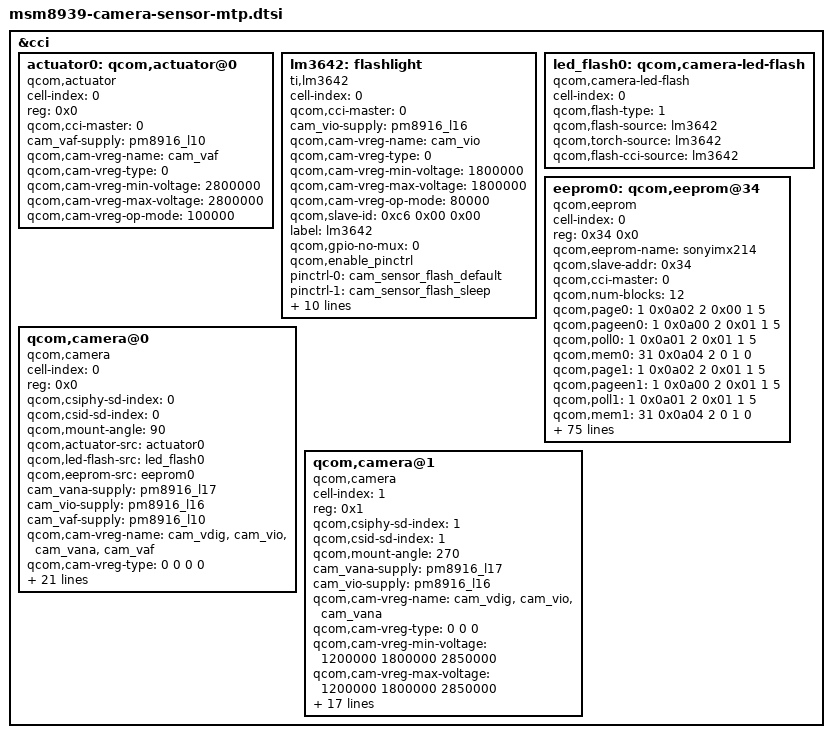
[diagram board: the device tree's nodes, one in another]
/*
 * Copyright (c) 2014, The Linux Foundation. All rights reserved.
 *
 * This program is free software; you can redistribute it and/or modify
 * it under the terms of the GNU General Public License version 2 and
 * only version 2 as published by the Free Software Foundation.
 *
 * This program is distributed in the hope that it will be useful,
 * but WITHOUT ANY WARRANTY; without even the implied warranty of
 * MERCHANTABILITY or FITNESS FOR A PARTICULAR PURPOSE.  See the
 * GNU General Public License for more details.
 */

&cci {
	actuator0: qcom,actuator@0 {
		cell-index = <0>;
		reg = <0x0>;
		compatible = "qcom,actuator";
		qcom,cci-master = <0>;
		cam_vaf-supply = <&pm8916_l10>;
		qcom,cam-vreg-name = "cam_vaf";
		qcom,cam-vreg-type = <0>;
		qcom,cam-vreg-min-voltage = <2800000>;
		qcom,cam-vreg-max-voltage = <2800000>;
		qcom,cam-vreg-op-mode = <100000>;
	};

	lm3642: flashlight {
		cell-index = <0>;
		compatible = "ti,lm3642";
		status = "okay";
		qcom,cci-master = <0>;
		cam_vio-supply = <&pm8916_l16>;
		qcom,cam-vreg-name = "cam_vio";
		qcom,cam-vreg-type = <0>;
		qcom,cam-vreg-min-voltage = <1800000>;
		qcom,cam-vreg-max-voltage = <1800000>;
		qcom,cam-vreg-op-mode = <80000>;
		qcom,slave-id = <0xc6 0x00 0x00>;
		label = "lm3642";
		qcom,gpio-no-mux = <0>;
		qcom,enable_pinctrl;
		pinctrl-names = "cam_flash_default", "cam_flash_suspend";
		pinctrl-0 = <&cam_sensor_flash_default>;
		pinctrl-1 = <&cam_sensor_flash_sleep>;
		gpios = <&msm_gpio 32 0>, <&msm_gpio 31 0>;
		qcom,gpio-flash-en = <0>;
		qcom,gpio-flash-now = <1>;
		qcom,gpio-req-tbl-num = <0 1>;
		qcom,gpio-req-tbl-flags = <0 0>;
		qcom,gpio-req-tbl-label = "FLASH_EN", "FLASH_NOW";
		qcom,current = <200>;
		qcom,max-current = <950>;
		linux,name = "flashlight";
		linux,default-trigger = "flashlight-trigger";
	};

	led_flash0: qcom,camera-led-flash {
		cell-index = <0>;
		compatible = "qcom,camera-led-flash";
		qcom,flash-type = <1>;
		qcom,flash-source = <&lm3642>;
		qcom,torch-source = <&lm3642>;
		qcom,flash-cci-source = <&lm3642>;
	};

	eeprom0: qcom,eeprom@34 {
		cell-index = <0>;
		reg = <0x34 0x0>;
		qcom,eeprom-name = "sonyimx214";
		compatible = "qcom,eeprom";
		qcom,slave-addr = <0x34>;
		qcom,cci-master = <0>;
		qcom,num-blocks = <12>;

		qcom,page0 = <1 0x0a02 2 0x00 1 5>;
		qcom,pageen0 = <1 0x0a00 2 0x01 1 5>;
		qcom,poll0 = <1 0x0a01 2 0x01 1 5>;
		qcom,mem0 = <31 0x0a04 2 0 1 0>;

		qcom,page1 = <1 0x0a02 2 0x01 1 5>;
		qcom,pageen1 = <1 0x0a00 2 0x01 1 5>;
		qcom,poll1 = <1 0x0a01 2 0x01 1 5>;
		qcom,mem1 = <31 0x0a04 2 0 1 0>;

		qcom,page2 = <1 0x0a02 2 0x02 1 5>;
		qcom,pageen2 = <1 0x0a00 2 0x01 1 5>;
		qcom,poll2 = <1 0x0a01 2 0x01 1 5>;
		qcom,mem2 = <31 0x0a04 2 0 1 0>;

		qcom,page3 = <1 0x0a02 2 0x03 1 5>;
		qcom,pageen3 = <1 0x0a00 2 0x01 1 5>;
		qcom,poll3 = <1 0x0a01 2 0x01 1 5>;
		qcom,mem3 = <31 0x0a04 2 0 1 0>;

		qcom,page4 = <1 0x0a02 2 0x04 1 5>;
		qcom,pageen4 = <1 0x0a00 2 0x01 1 5>;
		qcom,poll4 = <1 0x0a01 2 0x01 1 5>;
		qcom,mem4 = <31 0x0a04 2 0 1 0>;

		qcom,page5 = <1 0x0a02 2 0x05 1 5>;
		qcom,pageen5 = <1 0x0a00 2 0x01 1 5>;
		qcom,poll5 = <1 0x0a01 2 0x01 1 5>;
		qcom,mem5 = <31 0x0a04 2 0 1 0>;

		qcom,page6 = <1 0x0a02 2 0x06 1 5>;
		qcom,pageen6 = <1 0x0a00 2 0x01 1 5>;
		qcom,poll6 = <1 0x0a01 2 0x01 1 5>;
		qcom,mem6 = <31 0x0a04 2 0 1 0>;

		qcom,page7 = <1 0x0a02 2 0x07 1 5>;
		qcom,pageen7 = <1 0x0a00 2 0x01 1 5>;
		qcom,poll7 = <1 0x0a01 2 0x01 1 5>;
		qcom,mem7 = <31 0x0a04 2 0 1 0>;

		qcom,page8 = <1 0x0a02 2 0x08 1 5>;
		qcom,pageen8 = <1 0x0a00 2 0x01 1 5>;
		qcom,poll8 = <1 0x0a01 2 0x01 1 5>;
		qcom,mem8 = <31 0x0a04 2 0 1 0>;

		qcom,page9 = <1 0x0a02 2 0x09 1 5>;
		qcom,pageen9 = <1 0x0a00 2 0x01 1 5>;
		qcom,poll9 = <1 0x0a01 2 0x01 1 5>;
		qcom,mem9 = <31 0x0a04 2 0 1 0>;

		qcom,page10 = <1 0x0a02 2 0x0a 1 5>;
		qcom,pageen10 = <1 0x0a00 2 0x01 1 5>;
		qcom,poll10 = <1 0x0a01 2 0x01 1 5>;
		qcom,mem10 = <31 0x0a04 2 0 1 0>;

		qcom,page11 = <1 0x0a02 2 0x0b 1 5>;
		qcom,pageen11 = <1 0x0a00 2 0x01 1 5>;
		qcom,poll11 = <1 0x0a01 2 0x01 1 5>;
		qcom,mem11 = <31 0x0a04 2 0 1 0>;

		cam_vana-supply = <&pm8916_l17>;
		cam_vio-supply = <&pm8916_l16>;
		qcom,cam-vreg-name = "cam_vdig", "cam_vio", "cam_vana";
		qcom,cam-vreg-type = <0 0 0>;
		qcom,cam-vreg-min-voltage = <1050000 1800000 2850000>;
		qcom,cam-vreg-max-voltage = <1050000 1800000 2850000>;
		qcom,cam-vreg-op-mode = <0 0 80000>;
		pinctrl-names = "cam_default", "cam_suspend";
		pinctrl-0 = <&cam_sensor_mclk0_default
				&cam_sensor_rear_default>;
		pinctrl-1 = <&cam_sensor_mclk0_sleep &cam_sensor_rear_sleep>;
		qcom,gpio-no-mux = <0>;
		gpios = <&msm_gpio 26 0>,
			<&msm_gpio 35 0>,
			<&msm_gpio 52 0>;
		qcom,gpio-reset = <1>;
		qcom,gpio-vdig = <2>;
		qcom,gpio-req-tbl-num = <0 1 2>;
		qcom,gpio-req-tbl-flags = <1 0 0>;
		qcom,gpio-req-tbl-label = "CAMIF_MCLK0",
			"CAM_RESET0",
			"CAM_DVIG0";
		qcom,gpio-set-tbl-delay = <1000 30000 30000>;
		status = "ok";
		qcom,cam-power-seq-type = "sensor_vreg", "sensor_gpio",
			"sensor_vreg", "sensor_gpio", "sensor_clk";
		qcom,cam-power-seq-val = "cam_vio", "sensor_gpio_vdig",
			"cam_vana", "sensor_gpio_reset", "sensor_cam_mclk";
		qcom,cam-power-seq-cfg-val = <1 1 1 1 24000000>;
		qcom,cam-power-seq-delay = <1 1 1 30 5>;
		clocks = <&clock_gcc clk_mclk0_clk_src>,
				<&clock_gcc clk_gcc_camss_mclk0_clk>;
		clock-names = "cam_src_clk", "cam_clk";

		qcom,csi-lane-assign = <0x4320>;
		qcom,csi-lane-mask = <0x1F>;
	};

	qcom,camera@0 {
		cell-index = <0>;
		compatible = "qcom,camera";
		reg = <0x0>;
		qcom,csiphy-sd-index = <0>;
		qcom,csid-sd-index = <0>;
		qcom,mount-angle = <90>;
		qcom,actuator-src = <&actuator0>;
		qcom,led-flash-src = <&led_flash0>;
		qcom,eeprom-src = <&eeprom0>;
		cam_vana-supply = <&pm8916_l17>;
		cam_vio-supply = <&pm8916_l16>;
		cam_vaf-supply = <&pm8916_l10>;
		qcom,cam-vreg-name = "cam_vdig", "cam_vio", "cam_vana",
							"cam_vaf";
		qcom,cam-vreg-type = <0 0 0 0>;
		qcom,cam-vreg-min-voltage = <1050000 1800000 2850000 2800000>;
		qcom,cam-vreg-max-voltage = <1050000 1800000 2850000 2800000>;
		qcom,cam-vreg-op-mode = <0 0 80000 100000>;
		pinctrl-names = "cam_default", "cam_suspend";
		pinctrl-0 = <&cam_sensor_mclk0_default
				&cam_sensor_rear_default>;
		pinctrl-1 = <&cam_sensor_mclk0_sleep &cam_sensor_rear_sleep>;
		gpios = <&msm_gpio 26 0>,
			<&msm_gpio 35 0>,
			<&msm_gpio 52 0>;
		qcom,gpio-reset = <1>;
		qcom,gpio-vdig = <2>;
		qcom,gpio-req-tbl-num = <0 1 2>;
		qcom,gpio-req-tbl-flags = <1 0 0>;
		qcom,gpio-req-tbl-label = "CAMIF_MCLK0",
			"CAM_RESET0",
			"CAM_DVIG0";
		qcom,sensor-position = <0>;
		qcom,sensor-mode = <0>;
		qcom,cci-master = <0>;
		status = "ok";
		clocks = <&clock_gcc clk_mclk0_clk_src>,
				<&clock_gcc clk_gcc_camss_mclk0_clk>;
		clock-names = "cam_src_clk", "cam_clk";
	};

	qcom,camera@1 {
		cell-index = <1>;
		compatible = "qcom,camera";
		reg = <0x1>;
		qcom,csiphy-sd-index = <1>;
		qcom,csid-sd-index = <1>;
		qcom,mount-angle = <270>;
		cam_vana-supply = <&pm8916_l17>;
		cam_vio-supply = <&pm8916_l16>;
		qcom,cam-vreg-name = "cam_vdig", "cam_vio", "cam_vana";
		qcom,cam-vreg-type = <0 0 0>;
		qcom,cam-vreg-min-voltage = <1200000 1800000 2850000>;
		qcom,cam-vreg-max-voltage = <1200000 1800000 2850000>;
		qcom,cam-vreg-op-mode = <0 80000 0>;
		pinctrl-names = "cam_default", "cam_suspend";
		pinctrl-0 = <&cam_sensor_mclk1_default
				&cam_sensor_front_default>;
		pinctrl-1 = <&cam_sensor_mclk1_sleep &cam_sensor_front_sleep>;
		gpios = <&msm_gpio 27 0>,
			<&msm_gpio 28 0>,
			<&msm_gpio 17 0>;
		qcom,gpio-reset = <1>;
		qcom,gpio-vdig = <2>;
		qcom,gpio-req-tbl-num = <0 1 2>;
		qcom,gpio-req-tbl-flags = <1 0 0>;
		qcom,gpio-req-tbl-label = "CAMIF_MCLK1",
			"CAM_RESET1",
			"CAM_DVIG1";
		qcom,sensor-position = <1>;
		qcom,sensor-mode = <0>;
		qcom,cci-master = <0>;
		status = "ok";
		clocks = <&clock_gcc clk_mclk1_clk_src>,
				<&clock_gcc clk_gcc_camss_mclk1_clk>;
		clock-names = "cam_src_clk", "cam_clk";
	};
};
